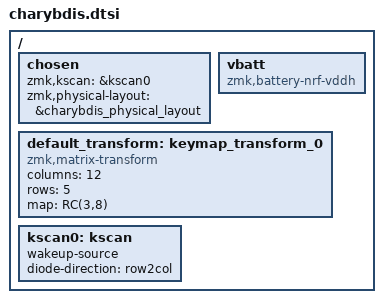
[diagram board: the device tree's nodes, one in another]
#include <dt-bindings/zmk/matrix_transform.h>
#include "charybdis-layouts.dtsi"

/ {
    // chosen {
    //     zmk,kscan = &kscan0;
    //     zmk,matrix_transform = &default_transform;
    // };
    chosen {
        zmk,kscan = &kscan0;
        zmk,physical-layout = &charybdis_physical_layout;
    };

    vbatt: vbatt {
	compatible = "zmk,battery-nrf-vddh";
    };

    default_transform: keymap_transform_0 {
        compatible = "zmk,matrix-transform";
        columns = <12>;
        rows = <5>;

        map = <
  RC(3,8)
        >;
    };

    kscan0: kscan {
        wakeup-source;
        diode-direction = "row2col";
    };
};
